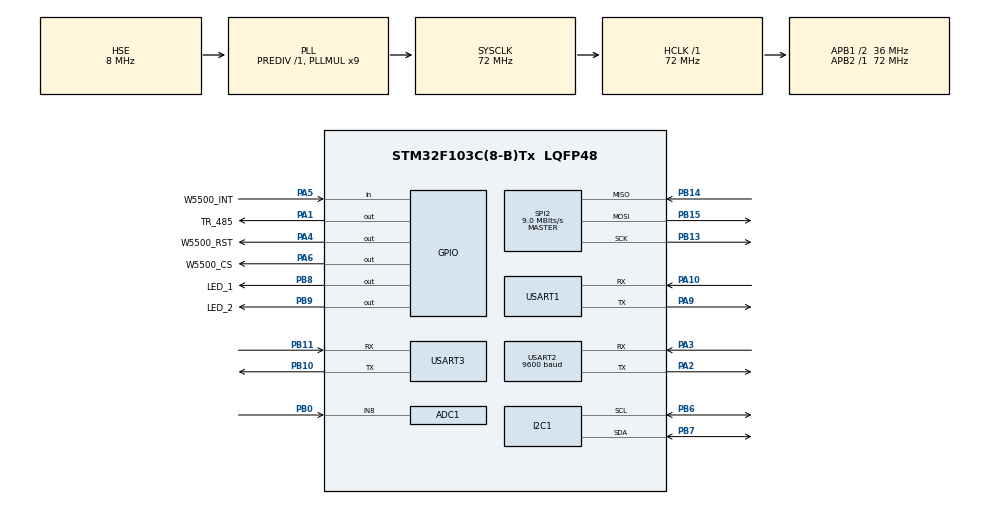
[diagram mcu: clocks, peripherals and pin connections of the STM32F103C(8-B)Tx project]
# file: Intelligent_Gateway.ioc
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ADC1.Channel-0\#ChannelRegularConversion=ADC_CHANNEL_8
ADC1.ContinuousConvMode=ENABLE
ADC1.NbrOfConversionFlag=1
ADC1.Rank-0\#ChannelRegularConversion=1
ADC1.SamplingTime-0\#ChannelRegularConversion=ADC_SAMPLETIME_1CYCLE_5
ADC1.master=1
I2C1.I2C_Mode=I2C_Standard
Mcu.Family=STM32F1
Mcu.Name=STM32F103C(8-B)Tx
Mcu.Package=LQFP48
NVIC.PriorityGroup=NVIC_PRIORITYGROUP_4
NVIC.TIM2_IRQn=true\:15\:0\:false\:false\:true\:false\:true\:true
NVIC.TimeBase=TIM2_IRQn
NVIC.TimeBaseIP=TIM2
NVIC.USART2_IRQn=true\:0\:0\:false\:false\:true\:true\:true\:true
NVIC.USART3_IRQn=true\:0\:0\:false\:false\:true\:true\:true\:true
PA1.GPIO_Label=TR_485
PA1.GPIO_Speed=GPIO_SPEED_FREQ_HIGH
PA1.Signal=GPIO_Output
PA10.Mode=Asynchronous
PA10.Signal=USART1_RX
PA13.Mode=Serial_Wire
PA13.Signal=SYS_JTMS-SWDIO
PA14.Mode=Serial_Wire
PA14.Signal=SYS_JTCK-SWCLK
PA2.Mode=Asynchronous
PA2.Signal=USART2_TX
PA3.Mode=Asynchronous
PA3.Signal=USART2_RX
PA4.GPIO_Label=W5500_RST
PA4.GPIO_Speed=GPIO_SPEED_FREQ_HIGH
PA4.PinState=GPIO_PIN_SET
PA4.Signal=GPIO_Output
PA5.GPIO_Label=W5500_INT
PA5.GPIO_PuPd=GPIO_PULLUP
PA5.Signal=GPIO_Input
PA6.GPIO_Label=W5500_CS
PA6.GPIO_Speed=GPIO_SPEED_FREQ_HIGH
PA6.PinState=GPIO_PIN_SET
PA6.Signal=GPIO_Output
PA9.Mode=Asynchronous
PA9.Signal=USART1_TX
PB0.Signal=ADCx_IN8
PB10.Mode=Asynchronous
PB10.Signal=USART3_TX
PB11.Mode=Asynchronous
PB11.Signal=USART3_RX
PB13.Mode=Full_Duplex_Master
PB13.Signal=SPI2_SCK
PB14.Mode=Full_Duplex_Master
PB14.Signal=SPI2_MISO
PB15.Mode=Full_Duplex_Master
PB15.Signal=SPI2_MOSI
PB6.Mode=I2C
PB6.Signal=I2C1_SCL
PB7.Mode=I2C
PB7.Signal=I2C1_SDA
PB8.GPIO_Label=LED_1
PB8.GPIO_Speed=GPIO_SPEED_FREQ_HIGH
PB8.PinState=GPIO_PIN_SET
PB8.Signal=GPIO_Output
PB9.GPIO_Label=LED_2
PB9.GPIO_Speed=GPIO_SPEED_FREQ_HIGH
PB9.PinState=GPIO_PIN_SET
PB9.Signal=GPIO_Output
PC14-OSC32_IN.Mode=LSE-External-Oscillator
PC14-OSC32_IN.Signal=RCC_OSC32_IN
PC15-OSC32_OUT.Mode=LSE-External-Oscillator
PC15-OSC32_OUT.Signal=RCC_OSC32_OUT
PD0-OSC_IN.Mode=HSE-External-Oscillator
PD0-OSC_IN.Signal=RCC_OSC_IN
PD1-OSC_OUT.Mode=HSE-External-Oscillator
PD1-OSC_OUT.Signal=RCC_OSC_OUT
ProjectManager.HeapSize=0x400
ProjectManager.StackSize=0x400
ProjectManager.TargetToolchain=MDK-ARM V5.32
RCC.ADCPresc=RCC_ADCPCLK2_DIV6
RCC.AHBFreq_Value=72000000
RCC.APB1CLKDivider=RCC_HCLK_DIV2
RCC.APB1Freq_Value=36000000
RCC.APB1TimFreq_Value=72000000
RCC.APB2Freq_Value=72000000
RCC.APB2TimFreq_Value=72000000
RCC.HCLKFreq_Value=72000000
RCC.PLLMUL=RCC_PLL_MUL9
RCC.PLLSourceVirtual=RCC_PLLSOURCE_HSE
RCC.SYSCLKFreq_VALUE=72000000
RCC.SYSCLKSource=RCC_SYSCLKSOURCE_PLLCLK
RCC.USBFreq_Value=72000000
SH.ADCx_IN8.0=ADC1_IN8,IN8
SPI2.BaudRatePrescaler=SPI_BAUDRATEPRESCALER_4
SPI2.CalculateBaudRate=9.0 MBits/s
SPI2.Direction=SPI_DIRECTION_2LINES
SPI2.Mode=SPI_MODE_MASTER
SPI2.VirtualType=VM_MASTER
USART1.VirtualMode=VM_ASYNC
USART2.BaudRate=9600
USART2.VirtualMode=VM_ASYNC
USART3.VirtualMode=VM_ASYNC
VP_SYS_VS_tim2.Mode=TIM2
board=custom

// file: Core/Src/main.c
/* USER CODE BEGIN Header */
/**
 ******************************************************************************
 * @file           : main.c
 * @brief          : Main program body
 ******************************************************************************
 * @attention
 *
 * Copyright (c) 2024 STMicroelectronics.
 * All rights reserved.
 *
 * This software is licensed under terms that can be found in the LICENSE file
 * in the root directory of this software component.
 * If no LICENSE file comes with this software, it is provided AS-IS.
 *
 ******************************************************************************
 */
/* USER CODE END Header */
#include "main.h"
#include "adc.h"
#include "i2c.h"
#include "spi.h"
#include "usart.h"
#include "gpio.h"

/* USER CODE BEGIN Includes */
#include "FreeRTOS_Task.h"
#include "eth.h"
#include "oled.h"
#include "modbus.h"

/* USER CODE END Includes */

void SystemClock_Config(void);

int main(void)
{

  /* MCU Configuration--------------------------------------------------------*/

  /* Reset of all peripherals, Initializes the Flash interface and the Systick. */
  HAL_Init();

  /* Configure the system clock */
  SystemClock_Config();

  /* Initialize all configured peripherals */
  MX_GPIO_Init();
  MX_SPI2_Init();
  MX_USART1_UART_Init();
  MX_USART2_UART_Init();
  MX_USART3_UART_Init();
  MX_I2C1_Init();
  MX_ADC1_Init();
  /* USER CODE BEGIN 2 */
  printf("Program startup!\r\n");
  FreeRTOS_Task_Start();
  /* USER CODE END 2 */

  /* Infinite loop */
  /* USER CODE BEGIN WHILE */
  //ETH_Init();
    while (1) {
    /* USER CODE END WHILE */

    }
}

void SystemClock_Config(void)
{
  RCC_OscInitTypeDef RCC_OscInitStruct = {0};
  RCC_ClkInitTypeDef RCC_ClkInitStruct = {0};
  RCC_PeriphCLKInitTypeDef PeriphClkInit = {0};

  /** Initializes the RCC Oscillators according to the specified parameters
  * in the RCC_OscInitTypeDef structure.
  */
  RCC_OscInitStruct.OscillatorType = RCC_OSCILLATORTYPE_HSE;
  RCC_OscInitStruct.HSEState = RCC_HSE_ON;
  RCC_OscInitStruct.HSEPredivValue = RCC_HSE_PREDIV_DIV1;
  RCC_OscInitStruct.HSIState = RCC_HSI_ON;
  RCC_OscInitStruct.PLL.PLLState = RCC_PLL_ON;
  RCC_OscInitStruct.PLL.PLLSource = RCC_PLLSOURCE_HSE;
  RCC_OscInitStruct.PLL.PLLMUL = RCC_PLL_MUL9;
  if (HAL_RCC_OscConfig(&RCC_OscInitStruct) != HAL_OK)
  {
    Error_Handler();
  }

  /** Initializes the CPU, AHB and APB buses clocks
  */
  RCC_ClkInitStruct.ClockType = RCC_CLOCKTYPE_HCLK|RCC_CLOCKTYPE_SYSCLK
                              |RCC_CLOCKTYPE_PCLK1|RCC_CLOCKTYPE_PCLK2;
  RCC_ClkInitStruct.SYSCLKSource = RCC_SYSCLKSOURCE_PLLCLK;
  RCC_ClkInitStruct.AHBCLKDivider = RCC_SYSCLK_DIV1;
  RCC_ClkInitStruct.APB1CLKDivider = RCC_HCLK_DIV2;
  RCC_ClkInitStruct.APB2CLKDivider = RCC_HCLK_DIV1;

  if (HAL_RCC_ClockConfig(&RCC_ClkInitStruct, FLASH_LATENCY_2) != HAL_OK)
  {
    Error_Handler();
  }
  PeriphClkInit.PeriphClockSelection = RCC_PERIPHCLK_ADC;
  PeriphClkInit.AdcClockSelection = RCC_ADCPCLK2_DIV6;
  if (HAL_RCCEx_PeriphCLKConfig(&PeriphClkInit) != HAL_OK)
  {
    Error_Handler();
  }
}

void HAL_TIM_PeriodElapsedCallback(TIM_HandleTypeDef *htim)
{
  if (htim->Instance == TIM2) {
    HAL_IncTick();
  }
}

void Error_Handler(void)
{
    __disable_irq();
    while (1) {
    }
}
